# RP2040 register map
Vendor: Raspberry Pi; Series: RP; File version: 0.1
CPU: CM0PLUS r0p1, little endian, MPU, no FPU, VTOR, 2 interrupt priority bits, 32 interrupts
Registers are 32-bit, read-write, reset 0x0 unless marked. A register's access mark holds for its fields unless they carry their own. Offsets are from the block's base; [hi:lo] are bit positions; {n}, {i} and the like mark numbered series; 'fields as' and 'values as' point back to an identical list.

## IO_BANK0
Base 0x40014000
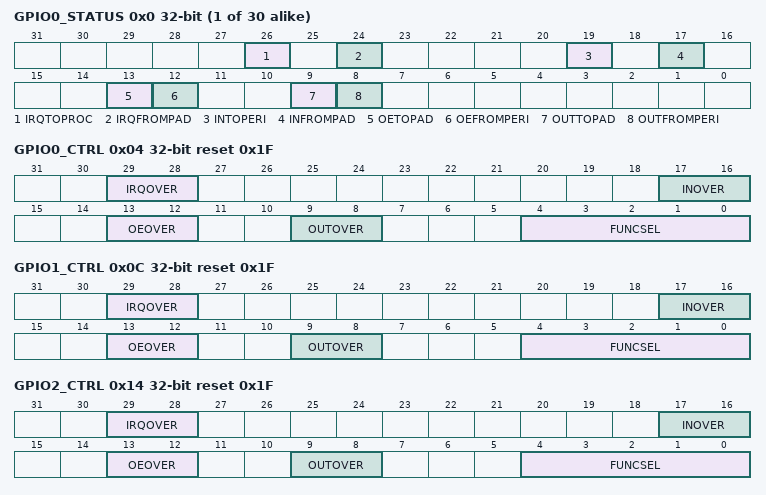
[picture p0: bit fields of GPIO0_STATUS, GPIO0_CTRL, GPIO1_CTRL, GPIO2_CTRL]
{0x0+8i} GPIO{i}_STATUS (i=0..29) — GPIO status
  [26] IRQTOPROC ro — interrupt to processors, after override is applied
  [24] IRQFROMPAD ro — interrupt from pad before override is applied
  [19] INTOPERI ro — input signal to peripheral, after override is applied
  [17] INFROMPAD ro — input signal from pad, before override is applied
  [13] OETOPAD ro — output enable to pad after register override is applied
  [12] OEFROMPERI ro — output enable from selected peripheral, before register override is applied
  [9] OUTTOPAD ro — output signal to pad after register override is applied
  [8] OUTFROMPERI ro — output signal from selected peripheral, before register override is applied
0x04 GPIO0_CTRL reset 0x1F — GPIO control including function select and overrides.
  [29:28] IRQOVER
    0=NORMAL (don't invert the interrupt); 1=INVERT (invert the interrupt); 2=LOW (drive interrupt low); 3=HIGH (drive interrupt high)
  [17:16] INOVER
    0=NORMAL (don't invert the peri input); 1=INVERT (invert the peri input); 2=LOW (drive peri input low); 3=HIGH (drive peri input high)
  [13:12] OEOVER
    0=NORMAL (drive output enable from peripheral signal selected by funcsel); 1=INVERT (drive output enable from inverse of peripheral signal selected by funcsel); 2=DISABLE (disable output); 3=ENABLE (enable output)
  [9:8] OUTOVER
    0=NORMAL (drive output from peripheral signal selected by funcsel); 1=INVERT (drive output from inverse of peripheral signal selected by funcsel); 2=LOW (drive output low); 3=HIGH (drive output high)
  [4:0] FUNCSEL — 0-31 -> selects pin function according to the gpio table 31 == NULL
    0=jtag_tck; 1=spi0_rx; 2=uart0_tx; 3=i2c0_sda; 4=pwm_a_0; 5=sio_0; 6=pio0_0; 7=pio1_0; 9=usb_muxing_overcurr_detect; 31=null
0x0C GPIO1_CTRL reset 0x1F — GPIO control including function select and overrides.
  [29:28] IRQOVER
    values as GPIO0_CTRL.IRQOVER
  [17:16] INOVER
    values as GPIO0_CTRL.INOVER
  [13:12] OEOVER
    values as GPIO0_CTRL.OEOVER
  [9:8] OUTOVER
    values as GPIO0_CTRL.OUTOVER
  [4:0] FUNCSEL — 0-31 -> selects pin function according to the gpio table 31 == NULL
    0=jtag_tms; 1=spi0_ss_n; 2=uart0_rx; 3=i2c0_scl; 4=pwm_b_0; 5=sio_1; 6=pio0_1; 7=pio1_1; 9=usb_muxing_vbus_detect; 31=null
0x14 GPIO2_CTRL reset 0x1F — GPIO control including function select and overrides.
  [29:28] IRQOVER
    values as GPIO0_CTRL.IRQOVER
  [17:16] INOVER
    values as GPIO0_CTRL.INOVER
  [13:12] OEOVER
    values as GPIO0_CTRL.OEOVER
  [9:8] OUTOVER
    values as GPIO0_CTRL.OUTOVER
  [4:0] FUNCSEL — 0-31 -> selects pin function according to the gpio table 31 == NULL
    0=jtag_tdi; 1=spi0_sclk; 2=uart0_cts; 3=i2c1_sda; 4=pwm_a_1; 5=sio_2; 6=pio0_2; 7=pio1_2; 9=usb_muxing_vbus_en; 31=null
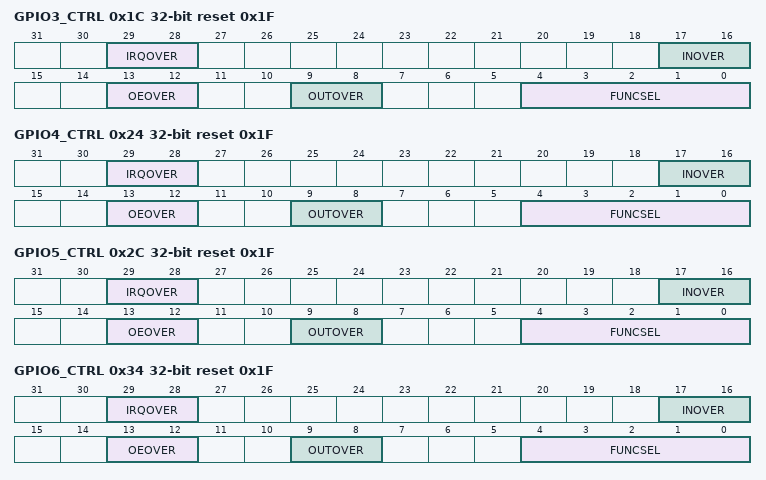
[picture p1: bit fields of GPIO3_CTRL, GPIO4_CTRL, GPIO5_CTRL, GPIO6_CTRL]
0x1C GPIO3_CTRL reset 0x1F — GPIO control including function select and overrides.
  [29:28] IRQOVER
    values as GPIO0_CTRL.IRQOVER
  [17:16] INOVER
    values as GPIO0_CTRL.INOVER
  [13:12] OEOVER
    values as GPIO0_CTRL.OEOVER
  [9:8] OUTOVER
    values as GPIO0_CTRL.OUTOVER
  [4:0] FUNCSEL — 0-31 -> selects pin function according to the gpio table 31 == NULL
    0=jtag_tdo; 1=spi0_tx; 2=uart0_rts; 3=i2c1_scl; 4=pwm_b_1; 5=sio_3; 6=pio0_3; 7=pio1_3; 9=usb_muxing_overcurr_detect; 31=null
0x24 GPIO4_CTRL reset 0x1F — GPIO control including function select and overrides.
  [29:28] IRQOVER
    values as GPIO0_CTRL.IRQOVER
  [17:16] INOVER
    values as GPIO0_CTRL.INOVER
  [13:12] OEOVER
    values as GPIO0_CTRL.OEOVER
  [9:8] OUTOVER
    values as GPIO0_CTRL.OUTOVER
  [4:0] FUNCSEL — 0-31 -> selects pin function according to the gpio table 31 == NULL
    1=spi0_rx; 2=uart1_tx; 3=i2c0_sda; 4=pwm_a_2; 5=sio_4; 6=pio0_4; 7=pio1_4; 9=usb_muxing_vbus_detect; 31=null
0x2C GPIO5_CTRL reset 0x1F — GPIO control including function select and overrides.
  [29:28] IRQOVER
    values as GPIO0_CTRL.IRQOVER
  [17:16] INOVER
    values as GPIO0_CTRL.INOVER
  [13:12] OEOVER
    values as GPIO0_CTRL.OEOVER
  [9:8] OUTOVER
    values as GPIO0_CTRL.OUTOVER
  [4:0] FUNCSEL — 0-31 -> selects pin function according to the gpio table 31 == NULL
    1=spi0_ss_n; 2=uart1_rx; 3=i2c0_scl; 4=pwm_b_2; 5=sio_5; 6=pio0_5; 7=pio1_5; 9=usb_muxing_vbus_en; 31=null
0x34 GPIO6_CTRL reset 0x1F — GPIO control including function select and overrides.
  [29:28] IRQOVER
    values as GPIO0_CTRL.IRQOVER
  [17:16] INOVER
    values as GPIO0_CTRL.INOVER
  [13:12] OEOVER
    values as GPIO0_CTRL.OEOVER
  [9:8] OUTOVER
    values as GPIO0_CTRL.OUTOVER
  [4:0] FUNCSEL — 0-31 -> selects pin function according to the gpio table 31 == NULL
    1=spi0_sclk; 2=uart1_cts; 3=i2c1_sda; 4=pwm_a_3; 5=sio_6; 6=pio0_6; 7=pio1_6; 8=usb_muxing_extphy_softcon; 9=usb_muxing_overcurr_detect; 31=null
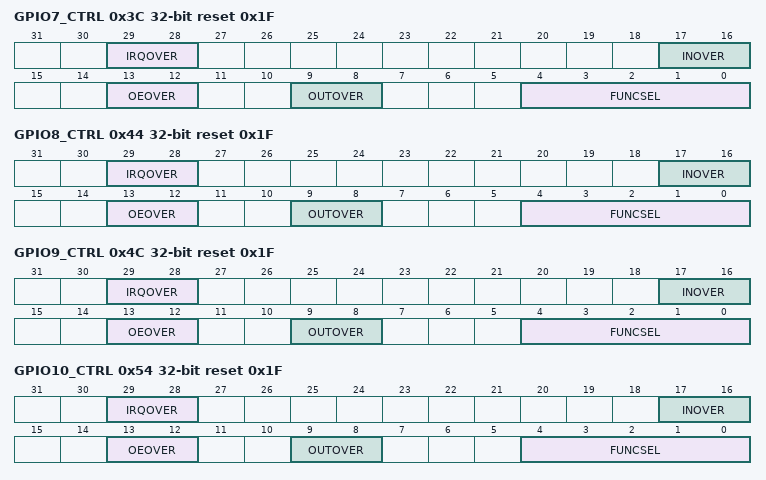
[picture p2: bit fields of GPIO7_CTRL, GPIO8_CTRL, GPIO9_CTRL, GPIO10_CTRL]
0x3C GPIO7_CTRL reset 0x1F — GPIO control including function select and overrides.
  [29:28] IRQOVER
    values as GPIO0_CTRL.IRQOVER
  [17:16] INOVER
    values as GPIO0_CTRL.INOVER
  [13:12] OEOVER
    values as GPIO0_CTRL.OEOVER
  [9:8] OUTOVER
    values as GPIO0_CTRL.OUTOVER
  [4:0] FUNCSEL — 0-31 -> selects pin function according to the gpio table 31 == NULL
    1=spi0_tx; 2=uart1_rts; 3=i2c1_scl; 4=pwm_b_3; 5=sio_7; 6=pio0_7; 7=pio1_7; 8=usb_muxing_extphy_oe_n; 9=usb_muxing_vbus_detect; 31=null
0x44 GPIO8_CTRL reset 0x1F — GPIO control including function select and overrides.
  [29:28] IRQOVER
    values as GPIO0_CTRL.IRQOVER
  [17:16] INOVER
    values as GPIO0_CTRL.INOVER
  [13:12] OEOVER
    values as GPIO0_CTRL.OEOVER
  [9:8] OUTOVER
    values as GPIO0_CTRL.OUTOVER
  [4:0] FUNCSEL — 0-31 -> selects pin function according to the gpio table 31 == NULL
    1=spi1_rx; 2=uart1_tx; 3=i2c0_sda; 4=pwm_a_4; 5=sio_8; 6=pio0_8; 7=pio1_8; 8=usb_muxing_extphy_rcv; 9=usb_muxing_vbus_en; 31=null
0x4C GPIO9_CTRL reset 0x1F — GPIO control including function select and overrides.
  [29:28] IRQOVER
    values as GPIO0_CTRL.IRQOVER
  [17:16] INOVER
    values as GPIO0_CTRL.INOVER
  [13:12] OEOVER
    values as GPIO0_CTRL.OEOVER
  [9:8] OUTOVER
    values as GPIO0_CTRL.OUTOVER
  [4:0] FUNCSEL — 0-31 -> selects pin function according to the gpio table 31 == NULL
    1=spi1_ss_n; 2=uart1_rx; 3=i2c0_scl; 4=pwm_b_4; 5=sio_9; 6=pio0_9; 7=pio1_9; 8=usb_muxing_extphy_vp; 9=usb_muxing_overcurr_detect; 31=null
0x54 GPIO10_CTRL reset 0x1F — GPIO control including function select and overrides.
  [29:28] IRQOVER
    values as GPIO0_CTRL.IRQOVER
  [17:16] INOVER
    values as GPIO0_CTRL.INOVER
  [13:12] OEOVER
    values as GPIO0_CTRL.OEOVER
  [9:8] OUTOVER
    values as GPIO0_CTRL.OUTOVER
  [4:0] FUNCSEL — 0-31 -> selects pin function according to the gpio table 31 == NULL
    1=spi1_sclk; 2=uart1_cts; 3=i2c1_sda; 4=pwm_a_5; 5=sio_10; 6=pio0_10; 7=pio1_10; 8=usb_muxing_extphy_vm; 9=usb_muxing_vbus_detect; 31=null
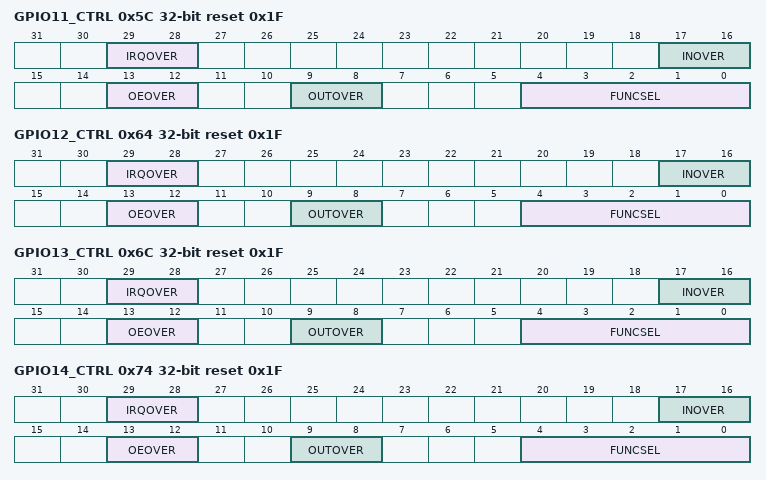
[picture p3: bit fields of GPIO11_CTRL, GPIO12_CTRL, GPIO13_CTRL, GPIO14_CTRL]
0x5C GPIO11_CTRL reset 0x1F — GPIO control including function select and overrides.
  [29:28] IRQOVER
    values as GPIO0_CTRL.IRQOVER
  [17:16] INOVER
    values as GPIO0_CTRL.INOVER
  [13:12] OEOVER
    values as GPIO0_CTRL.OEOVER
  [9:8] OUTOVER
    values as GPIO0_CTRL.OUTOVER
  [4:0] FUNCSEL — 0-31 -> selects pin function according to the gpio table 31 == NULL
    1=spi1_tx; 2=uart1_rts; 3=i2c1_scl; 4=pwm_b_5; 5=sio_11; 6=pio0_11; 7=pio1_11; 8=usb_muxing_extphy_suspnd; 9=usb_muxing_vbus_en; 31=null
0x64 GPIO12_CTRL reset 0x1F — GPIO control including function select and overrides.
  [29:28] IRQOVER
    values as GPIO0_CTRL.IRQOVER
  [17:16] INOVER
    values as GPIO0_CTRL.INOVER
  [13:12] OEOVER
    values as GPIO0_CTRL.OEOVER
  [9:8] OUTOVER
    values as GPIO0_CTRL.OUTOVER
  [4:0] FUNCSEL — 0-31 -> selects pin function according to the gpio table 31 == NULL
    1=spi1_rx; 2=uart0_tx; 3=i2c0_sda; 4=pwm_a_6; 5=sio_12; 6=pio0_12; 7=pio1_12; 8=usb_muxing_extphy_speed; 9=usb_muxing_overcurr_detect; 31=null
0x6C GPIO13_CTRL reset 0x1F — GPIO control including function select and overrides.
  [29:28] IRQOVER
    values as GPIO0_CTRL.IRQOVER
  [17:16] INOVER
    values as GPIO0_CTRL.INOVER
  [13:12] OEOVER
    values as GPIO0_CTRL.OEOVER
  [9:8] OUTOVER
    values as GPIO0_CTRL.OUTOVER
  [4:0] FUNCSEL — 0-31 -> selects pin function according to the gpio table 31 == NULL
    1=spi1_ss_n; 2=uart0_rx; 3=i2c0_scl; 4=pwm_b_6; 5=sio_13; 6=pio0_13; 7=pio1_13; 8=usb_muxing_extphy_vpo; 9=usb_muxing_vbus_detect; 31=null
0x74 GPIO14_CTRL reset 0x1F — GPIO control including function select and overrides.
  [29:28] IRQOVER
    values as GPIO0_CTRL.IRQOVER
  [17:16] INOVER
    values as GPIO0_CTRL.INOVER
  [13:12] OEOVER
    values as GPIO0_CTRL.OEOVER
  [9:8] OUTOVER
    values as GPIO0_CTRL.OUTOVER
  [4:0] FUNCSEL — 0-31 -> selects pin function according to the gpio table 31 == NULL
    1=spi1_sclk; 2=uart0_cts; 3=i2c1_sda; 4=pwm_a_7; 5=sio_14; 6=pio0_14; 7=pio1_14; 8=usb_muxing_extphy_vmo; 9=usb_muxing_vbus_en; 31=null
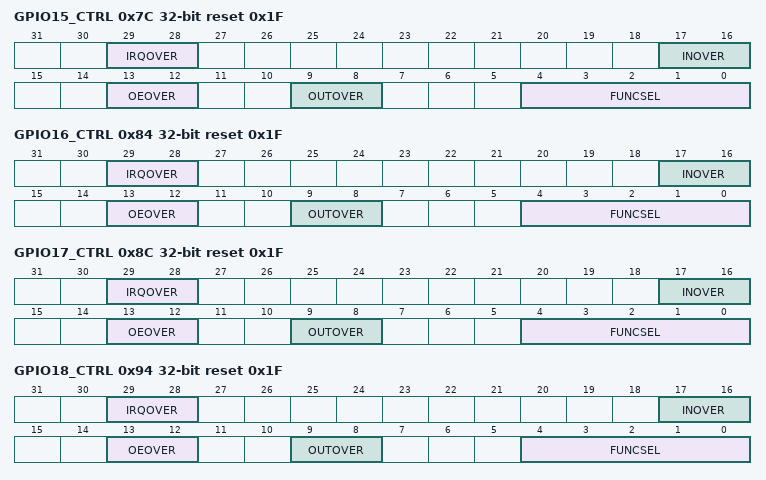
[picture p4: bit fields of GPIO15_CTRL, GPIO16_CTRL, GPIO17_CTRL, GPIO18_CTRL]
0x7C GPIO15_CTRL reset 0x1F — GPIO control including function select and overrides.
  [29:28] IRQOVER
    values as GPIO0_CTRL.IRQOVER
  [17:16] INOVER
    values as GPIO0_CTRL.INOVER
  [13:12] OEOVER
    values as GPIO0_CTRL.OEOVER
  [9:8] OUTOVER
    values as GPIO0_CTRL.OUTOVER
  [4:0] FUNCSEL — 0-31 -> selects pin function according to the gpio table 31 == NULL
    1=spi1_tx; 2=uart0_rts; 3=i2c1_scl; 4=pwm_b_7; 5=sio_15; 6=pio0_15; 7=pio1_15; 8=usb_muxing_digital_dp; 9=usb_muxing_overcurr_detect; 31=null
0x84 GPIO16_CTRL reset 0x1F — GPIO control including function select and overrides.
  [29:28] IRQOVER
    values as GPIO0_CTRL.IRQOVER
  [17:16] INOVER
    values as GPIO0_CTRL.INOVER
  [13:12] OEOVER
    values as GPIO0_CTRL.OEOVER
  [9:8] OUTOVER
    values as GPIO0_CTRL.OUTOVER
  [4:0] FUNCSEL — 0-31 -> selects pin function according to the gpio table 31 == NULL
    1=spi0_rx; 2=uart0_tx; 3=i2c0_sda; 4=pwm_a_0; 5=sio_16; 6=pio0_16; 7=pio1_16; 8=usb_muxing_digital_dm; 9=usb_muxing_vbus_detect; 31=null
0x8C GPIO17_CTRL reset 0x1F — GPIO control including function select and overrides.
  [29:28] IRQOVER
    values as GPIO0_CTRL.IRQOVER
  [17:16] INOVER
    values as GPIO0_CTRL.INOVER
  [13:12] OEOVER
    values as GPIO0_CTRL.OEOVER
  [9:8] OUTOVER
    values as GPIO0_CTRL.OUTOVER
  [4:0] FUNCSEL — 0-31 -> selects pin function according to the gpio table 31 == NULL
    1=spi0_ss_n; 2=uart0_rx; 3=i2c0_scl; 4=pwm_b_0; 5=sio_17; 6=pio0_17; 7=pio1_17; 9=usb_muxing_vbus_en; 31=null
0x94 GPIO18_CTRL reset 0x1F — GPIO control including function select and overrides.
  [29:28] IRQOVER
    values as GPIO0_CTRL.IRQOVER
  [17:16] INOVER
    values as GPIO0_CTRL.INOVER
  [13:12] OEOVER
    values as GPIO0_CTRL.OEOVER
  [9:8] OUTOVER
    values as GPIO0_CTRL.OUTOVER
  [4:0] FUNCSEL — 0-31 -> selects pin function according to the gpio table 31 == NULL
    1=spi0_sclk; 2=uart0_cts; 3=i2c1_sda; 4=pwm_a_1; 5=sio_18; 6=pio0_18; 7=pio1_18; 9=usb_muxing_overcurr_detect; 31=null
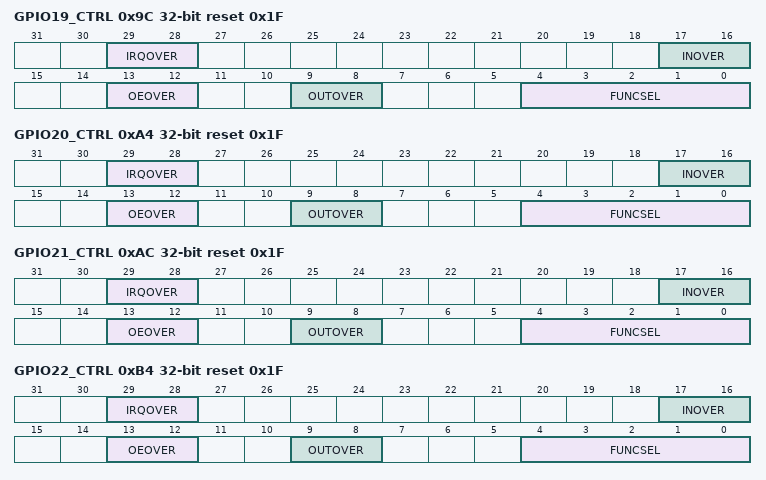
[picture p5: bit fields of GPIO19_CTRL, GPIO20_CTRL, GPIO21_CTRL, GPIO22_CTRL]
0x9C GPIO19_CTRL reset 0x1F — GPIO control including function select and overrides.
  [29:28] IRQOVER
    values as GPIO0_CTRL.IRQOVER
  [17:16] INOVER
    values as GPIO0_CTRL.INOVER
  [13:12] OEOVER
    values as GPIO0_CTRL.OEOVER
  [9:8] OUTOVER
    values as GPIO0_CTRL.OUTOVER
  [4:0] FUNCSEL — 0-31 -> selects pin function according to the gpio table 31 == NULL
    1=spi0_tx; 2=uart0_rts; 3=i2c1_scl; 4=pwm_b_1; 5=sio_19; 6=pio0_19; 7=pio1_19; 9=usb_muxing_vbus_detect; 31=null
0xA4 GPIO20_CTRL reset 0x1F — GPIO control including function select and overrides.
  [29:28] IRQOVER
    values as GPIO0_CTRL.IRQOVER
  [17:16] INOVER
    values as GPIO0_CTRL.INOVER
  [13:12] OEOVER
    values as GPIO0_CTRL.OEOVER
  [9:8] OUTOVER
    values as GPIO0_CTRL.OUTOVER
  [4:0] FUNCSEL — 0-31 -> selects pin function according to the gpio table 31 == NULL
    1=spi0_rx; 2=uart1_tx; 3=i2c0_sda; 4=pwm_a_2; 5=sio_20; 6=pio0_20; 7=pio1_20; 8=clocks_gpin_0; 9=usb_muxing_vbus_en; 31=null
0xAC GPIO21_CTRL reset 0x1F — GPIO control including function select and overrides.
  [29:28] IRQOVER
    values as GPIO0_CTRL.IRQOVER
  [17:16] INOVER
    values as GPIO0_CTRL.INOVER
  [13:12] OEOVER
    values as GPIO0_CTRL.OEOVER
  [9:8] OUTOVER
    values as GPIO0_CTRL.OUTOVER
  [4:0] FUNCSEL — 0-31 -> selects pin function according to the gpio table 31 == NULL
    1=spi0_ss_n; 2=uart1_rx; 3=i2c0_scl; 4=pwm_b_2; 5=sio_21; 6=pio0_21; 7=pio1_21; 8=clocks_gpout_0; 9=usb_muxing_overcurr_detect; 31=null
0xB4 GPIO22_CTRL reset 0x1F — GPIO control including function select and overrides.
  [29:28] IRQOVER
    values as GPIO0_CTRL.IRQOVER
  [17:16] INOVER
    values as GPIO0_CTRL.INOVER
  [13:12] OEOVER
    values as GPIO0_CTRL.OEOVER
  [9:8] OUTOVER
    values as GPIO0_CTRL.OUTOVER
  [4:0] FUNCSEL — 0-31 -> selects pin function according to the gpio table 31 == NULL
    1=spi0_sclk; 2=uart1_cts; 3=i2c1_sda; 4=pwm_a_3; 5=sio_22; 6=pio0_22; 7=pio1_22; 8=clocks_gpin_1; 9=usb_muxing_vbus_detect; 31=null
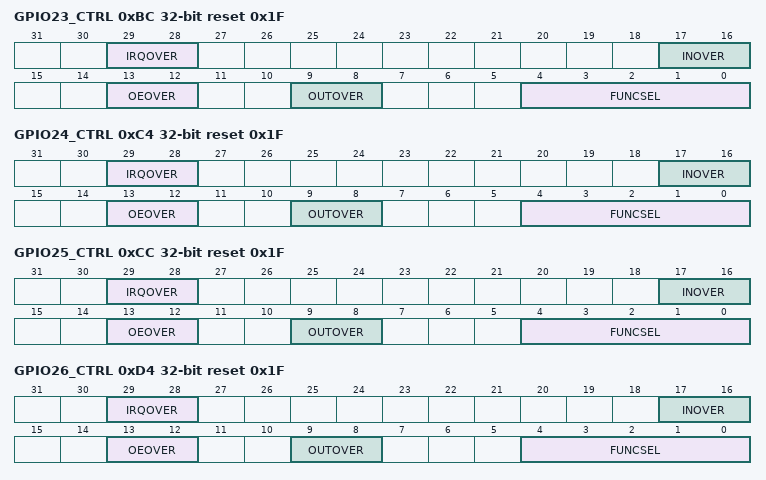
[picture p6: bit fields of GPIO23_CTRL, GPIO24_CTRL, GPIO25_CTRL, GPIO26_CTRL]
0xBC GPIO23_CTRL reset 0x1F — GPIO control including function select and overrides.
  [29:28] IRQOVER
    values as GPIO0_CTRL.IRQOVER
  [17:16] INOVER
    values as GPIO0_CTRL.INOVER
  [13:12] OEOVER
    values as GPIO0_CTRL.OEOVER
  [9:8] OUTOVER
    values as GPIO0_CTRL.OUTOVER
  [4:0] FUNCSEL — 0-31 -> selects pin function according to the gpio table 31 == NULL
    1=spi0_tx; 2=uart1_rts; 3=i2c1_scl; 4=pwm_b_3; 5=sio_23; 6=pio0_23; 7=pio1_23; 8=clocks_gpout_1; 9=usb_muxing_vbus_en; 31=null
0xC4 GPIO24_CTRL reset 0x1F — GPIO control including function select and overrides.
  [29:28] IRQOVER
    values as GPIO0_CTRL.IRQOVER
  [17:16] INOVER
    values as GPIO0_CTRL.INOVER
  [13:12] OEOVER
    values as GPIO0_CTRL.OEOVER
  [9:8] OUTOVER
    values as GPIO0_CTRL.OUTOVER
  [4:0] FUNCSEL — 0-31 -> selects pin function according to the gpio table 31 == NULL
    1=spi1_rx; 2=uart1_tx; 3=i2c0_sda; 4=pwm_a_4; 5=sio_24; 6=pio0_24; 7=pio1_24; 8=clocks_gpout_2; 9=usb_muxing_overcurr_detect; 31=null
0xCC GPIO25_CTRL reset 0x1F — GPIO control including function select and overrides.
  [29:28] IRQOVER
    values as GPIO0_CTRL.IRQOVER
  [17:16] INOVER
    values as GPIO0_CTRL.INOVER
  [13:12] OEOVER
    values as GPIO0_CTRL.OEOVER
  [9:8] OUTOVER
    values as GPIO0_CTRL.OUTOVER
  [4:0] FUNCSEL — 0-31 -> selects pin function according to the gpio table 31 == NULL
    1=spi1_ss_n; 2=uart1_rx; 3=i2c0_scl; 4=pwm_b_4; 5=sio_25; 6=pio0_25; 7=pio1_25; 8=clocks_gpout_3; 9=usb_muxing_vbus_detect; 31=null
0xD4 GPIO26_CTRL reset 0x1F — GPIO control including function select and overrides.
  [29:28] IRQOVER
    values as GPIO0_CTRL.IRQOVER
  [17:16] INOVER
    values as GPIO0_CTRL.INOVER
  [13:12] OEOVER
    values as GPIO0_CTRL.OEOVER
  [9:8] OUTOVER
    values as GPIO0_CTRL.OUTOVER
  [4:0] FUNCSEL — 0-31 -> selects pin function according to the gpio table 31 == NULL
    1=spi1_sclk; 2=uart1_cts; 3=i2c1_sda; 4=pwm_a_5; 5=sio_26; 6=pio0_26; 7=pio1_26; 9=usb_muxing_vbus_en; 31=null
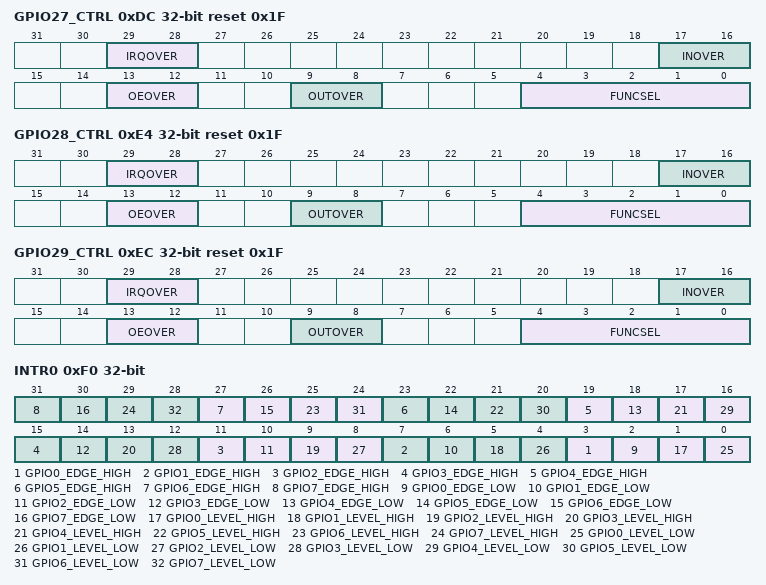
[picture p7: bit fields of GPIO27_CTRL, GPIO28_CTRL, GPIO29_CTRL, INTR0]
0xDC GPIO27_CTRL reset 0x1F — GPIO control including function select and overrides.
  [29:28] IRQOVER
    values as GPIO0_CTRL.IRQOVER
  [17:16] INOVER
    values as GPIO0_CTRL.INOVER
  [13:12] OEOVER
    values as GPIO0_CTRL.OEOVER
  [9:8] OUTOVER
    values as GPIO0_CTRL.OUTOVER
  [4:0] FUNCSEL — 0-31 -> selects pin function according to the gpio table 31 == NULL
    1=spi1_tx; 2=uart1_rts; 3=i2c1_scl; 4=pwm_b_5; 5=sio_27; 6=pio0_27; 7=pio1_27; 9=usb_muxing_overcurr_detect; 31=null
0xE4 GPIO28_CTRL reset 0x1F — GPIO control including function select and overrides.
  [29:28] IRQOVER
    values as GPIO0_CTRL.IRQOVER
  [17:16] INOVER
    values as GPIO0_CTRL.INOVER
  [13:12] OEOVER
    values as GPIO0_CTRL.OEOVER
  [9:8] OUTOVER
    values as GPIO0_CTRL.OUTOVER
  [4:0] FUNCSEL — 0-31 -> selects pin function according to the gpio table 31 == NULL
    1=spi1_rx; 2=uart0_tx; 3=i2c0_sda; 4=pwm_a_6; 5=sio_28; 6=pio0_28; 7=pio1_28; 9=usb_muxing_vbus_detect; 31=null
0xEC GPIO29_CTRL reset 0x1F — GPIO control including function select and overrides.
  [29:28] IRQOVER
    values as GPIO0_CTRL.IRQOVER
  [17:16] INOVER
    values as GPIO0_CTRL.INOVER
  [13:12] OEOVER
    values as GPIO0_CTRL.OEOVER
  [9:8] OUTOVER
    values as GPIO0_CTRL.OUTOVER
  [4:0] FUNCSEL — 0-31 -> selects pin function according to the gpio table 31 == NULL
    1=spi1_ss_n; 2=uart0_rx; 3=i2c0_scl; 4=pwm_b_6; 5=sio_29; 6=pio0_29; 7=pio1_29; 9=usb_muxing_vbus_en; 31=null
0xF0 INTR0 — Raw Interrupts
  [4n+3] GPIO{n}_EDGE_HIGH write-1-clears (n=0..7), [4n+2] GPIO{n}_EDGE_LOW write-1-clears (n=0..7), [4n+1] GPIO{n}_LEVEL_HIGH ro (n=0..7), [4n] GPIO{n}_LEVEL_LOW ro (n=0..7)
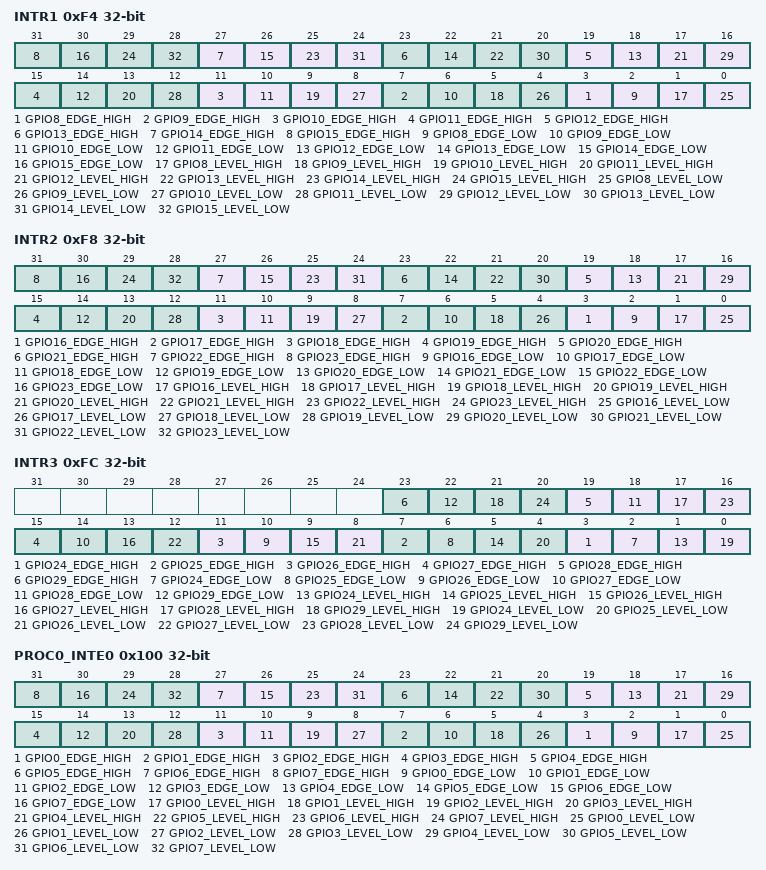
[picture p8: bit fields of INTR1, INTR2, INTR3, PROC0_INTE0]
0xF4 INTR1 — Raw Interrupts
  [4n-29] GPIO{n}_EDGE_HIGH write-1-clears (n=8..15), [4n-30] GPIO{n}_EDGE_LOW write-1-clears (n=8..15), [4n-31] GPIO{n}_LEVEL_HIGH ro (n=8..15), [4n-32] GPIO{n}_LEVEL_LOW ro (n=8..15)
0xF8 INTR2 — Raw Interrupts
  [4n-61] GPIO{n}_EDGE_HIGH write-1-clears (n=16..23), [4n-62] GPIO{n}_EDGE_LOW write-1-clears (n=16..23), [4n-63] GPIO{n}_LEVEL_HIGH ro (n=16..23), [4n-64] GPIO{n}_LEVEL_LOW ro (n=16..23)
0xFC INTR3 — Raw Interrupts
  [4n-93] GPIO{n}_EDGE_HIGH write-1-clears (n=24..29), [4n-94] GPIO{n}_EDGE_LOW write-1-clears (n=24..29), [4n-95] GPIO{n}_LEVEL_HIGH ro (n=24..29), [4n-96] GPIO{n}_LEVEL_LOW ro (n=24..29)
0x100 PROC0_INTE0 — Interrupt Enable for proc0
  [4n+3] GPIO{n}_EDGE_HIGH (n=0..7), [4n+2] GPIO{n}_EDGE_LOW (n=0..7), [4n+1] GPIO{n}_LEVEL_HIGH (n=0..7), [4n] GPIO{n}_LEVEL_LOW (n=0..7)
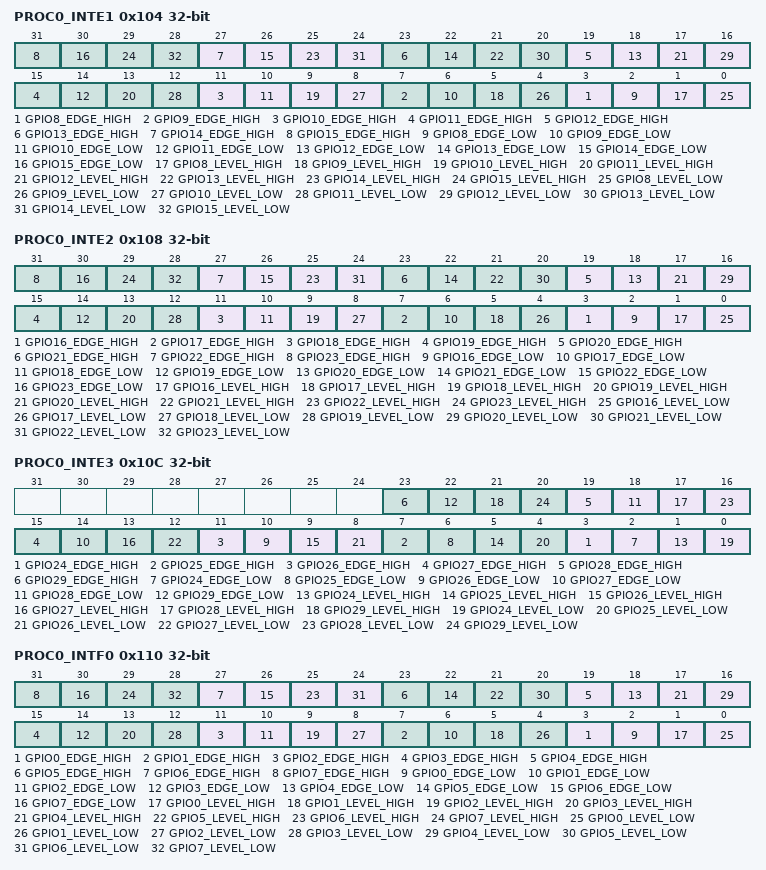
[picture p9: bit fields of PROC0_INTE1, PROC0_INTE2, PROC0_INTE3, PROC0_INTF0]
0x104 PROC0_INTE1 — Interrupt Enable for proc0
  [4n-29] GPIO{n}_EDGE_HIGH (n=8..15), [4n-30] GPIO{n}_EDGE_LOW (n=8..15), [4n-31] GPIO{n}_LEVEL_HIGH (n=8..15), [4n-32] GPIO{n}_LEVEL_LOW (n=8..15)
0x108 PROC0_INTE2 — Interrupt Enable for proc0
  [4n-61] GPIO{n}_EDGE_HIGH (n=16..23), [4n-62] GPIO{n}_EDGE_LOW (n=16..23), [4n-63] GPIO{n}_LEVEL_HIGH (n=16..23), [4n-64] GPIO{n}_LEVEL_LOW (n=16..23)
0x10C PROC0_INTE3 — Interrupt Enable for proc0
  [4n-93] GPIO{n}_EDGE_HIGH (n=24..29), [4n-94] GPIO{n}_EDGE_LOW (n=24..29), [4n-95] GPIO{n}_LEVEL_HIGH (n=24..29), [4n-96] GPIO{n}_LEVEL_LOW (n=24..29)
0x110 PROC0_INTF0 — Interrupt Force for proc0
  fields as PROC0_INTE0
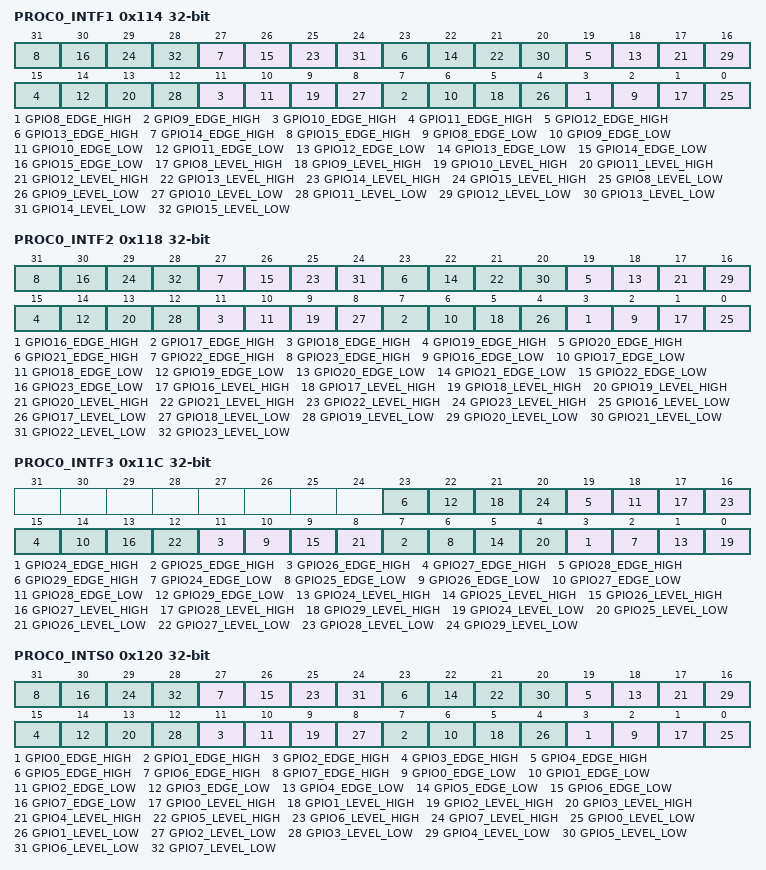
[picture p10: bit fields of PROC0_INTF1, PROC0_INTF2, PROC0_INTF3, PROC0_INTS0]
0x114 PROC0_INTF1 — Interrupt Force for proc0
  fields as PROC0_INTE1
0x118 PROC0_INTF2 — Interrupt Force for proc0
  fields as PROC0_INTE2
0x11C PROC0_INTF3 — Interrupt Force for proc0
  fields as PROC0_INTE3
0x120 PROC0_INTS0 — Interrupt status after masking & forcing for proc0
  [4n+3] GPIO{n}_EDGE_HIGH ro (n=0..7), [4n+2] GPIO{n}_EDGE_LOW ro (n=0..7), [4n+1] GPIO{n}_LEVEL_HIGH ro (n=0..7), [4n] GPIO{n}_LEVEL_LOW ro (n=0..7)
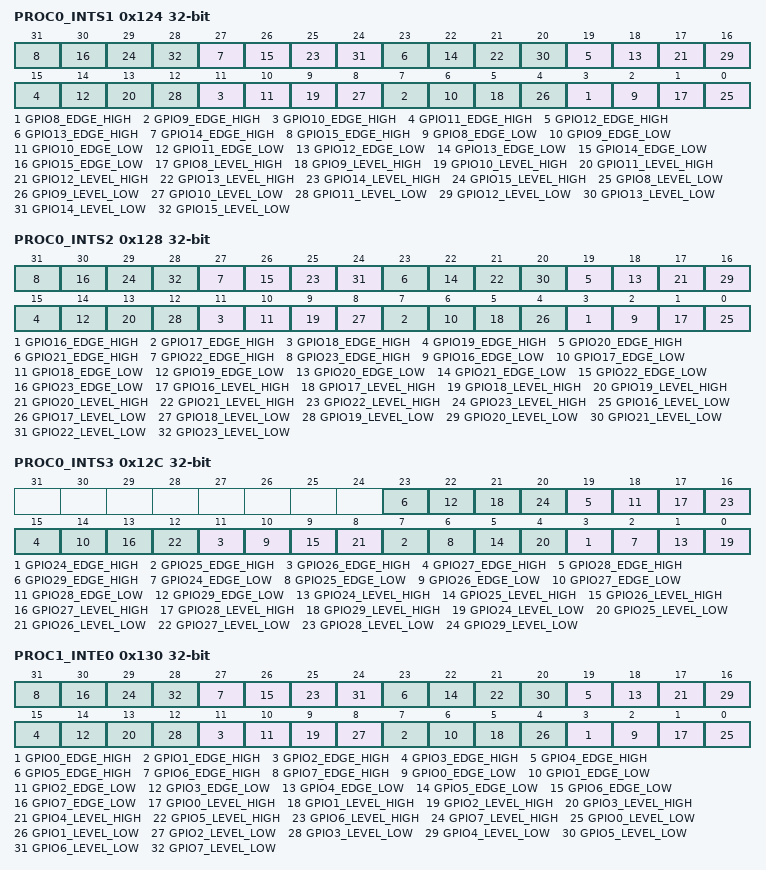
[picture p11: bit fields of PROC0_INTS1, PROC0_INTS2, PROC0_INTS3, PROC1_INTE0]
0x124 PROC0_INTS1 — Interrupt status after masking & forcing for proc0
  [4n-29] GPIO{n}_EDGE_HIGH ro (n=8..15), [4n-30] GPIO{n}_EDGE_LOW ro (n=8..15), [4n-31] GPIO{n}_LEVEL_HIGH ro (n=8..15), [4n-32] GPIO{n}_LEVEL_LOW ro (n=8..15)
0x128 PROC0_INTS2 — Interrupt status after masking & forcing for proc0
  [4n-61] GPIO{n}_EDGE_HIGH ro (n=16..23), [4n-62] GPIO{n}_EDGE_LOW ro (n=16..23), [4n-63] GPIO{n}_LEVEL_HIGH ro (n=16..23), [4n-64] GPIO{n}_LEVEL_LOW ro (n=16..23)
0x12C PROC0_INTS3 — Interrupt status after masking & forcing for proc0
  [4n-93] GPIO{n}_EDGE_HIGH ro (n=24..29), [4n-94] GPIO{n}_EDGE_LOW ro (n=24..29), [4n-95] GPIO{n}_LEVEL_HIGH ro (n=24..29), [4n-96] GPIO{n}_LEVEL_LOW ro (n=24..29)
0x130 PROC1_INTE0 — Interrupt Enable for proc1
  fields as PROC0_INTE0
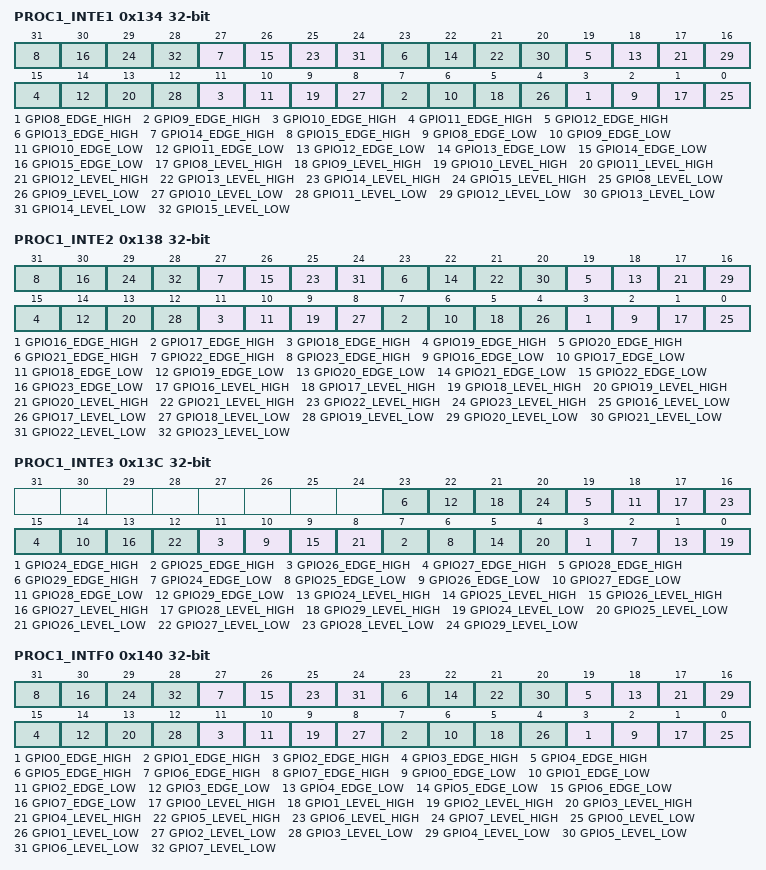
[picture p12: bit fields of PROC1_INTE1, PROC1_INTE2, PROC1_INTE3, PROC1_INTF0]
0x134 PROC1_INTE1 — Interrupt Enable for proc1
  fields as PROC0_INTE1
0x138 PROC1_INTE2 — Interrupt Enable for proc1
  fields as PROC0_INTE2
0x13C PROC1_INTE3 — Interrupt Enable for proc1
  fields as PROC0_INTE3
0x140 PROC1_INTF0 — Interrupt Force for proc1
  fields as PROC0_INTE0
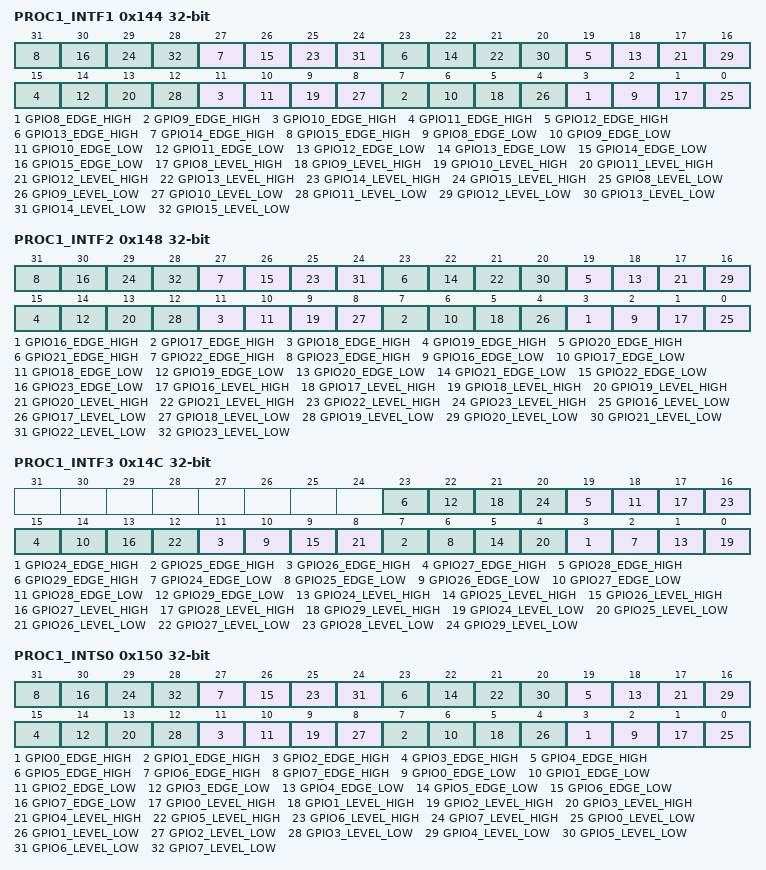
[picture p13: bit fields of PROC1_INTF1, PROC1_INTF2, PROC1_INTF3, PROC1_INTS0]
0x144 PROC1_INTF1 — Interrupt Force for proc1
  fields as PROC0_INTE1
0x148 PROC1_INTF2 — Interrupt Force for proc1
  fields as PROC0_INTE2
0x14C PROC1_INTF3 — Interrupt Force for proc1
  fields as PROC0_INTE3
0x150 PROC1_INTS0 — Interrupt status after masking & forcing for proc1
  fields as PROC0_INTS0
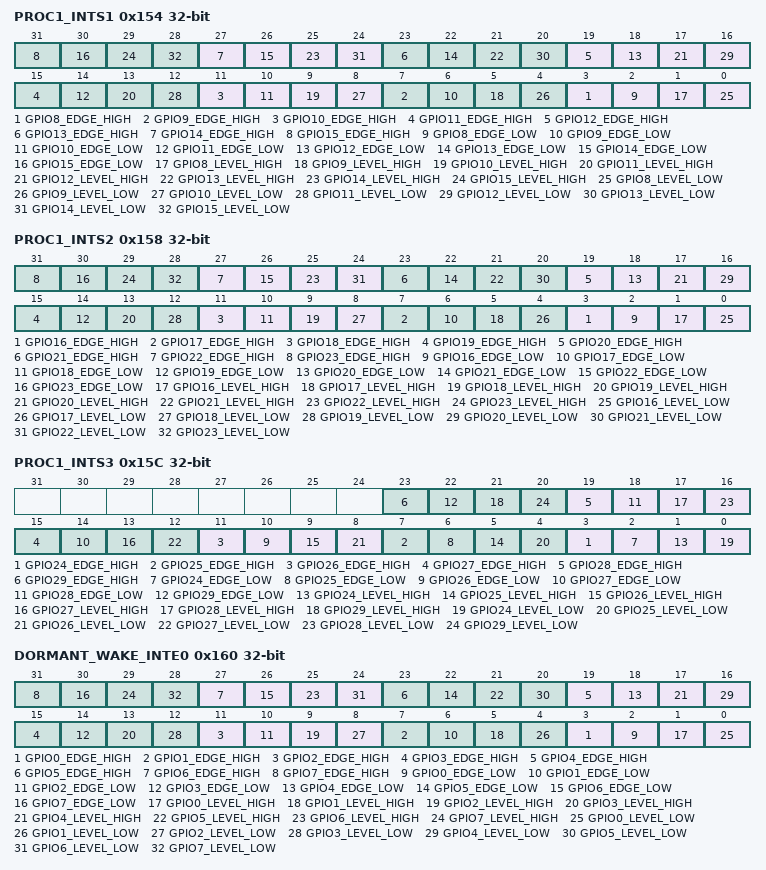
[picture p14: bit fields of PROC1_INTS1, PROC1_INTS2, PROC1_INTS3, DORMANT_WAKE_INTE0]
0x154 PROC1_INTS1 — Interrupt status after masking & forcing for proc1
  fields as PROC0_INTS1
0x158 PROC1_INTS2 — Interrupt status after masking & forcing for proc1
  fields as PROC0_INTS2
0x15C PROC1_INTS3 — Interrupt status after masking & forcing for proc1
  fields as PROC0_INTS3
0x160 DORMANT_WAKE_INTE0 — Interrupt Enable for dormant_wake
  fields as PROC0_INTE0
0x164 DORMANT_WAKE_INTE1 — Interrupt Enable for dormant_wake
  fields as PROC0_INTE1
0x168 DORMANT_WAKE_INTE2 — Interrupt Enable for dormant_wake
  fields as PROC0_INTE2
0x16C DORMANT_WAKE_INTE3 — Interrupt Enable for dormant_wake
  fields as PROC0_INTE3
0x170 DORMANT_WAKE_INTF0 — Interrupt Force for dormant_wake
  fields as PROC0_INTE0
0x174 DORMANT_WAKE_INTF1 — Interrupt Force for dormant_wake
  fields as PROC0_INTE1
0x178 DORMANT_WAKE_INTF2 — Interrupt Force for dormant_wake
  fields as PROC0_INTE2
0x17C DORMANT_WAKE_INTF3 — Interrupt Force for dormant_wake
  fields as PROC0_INTE3
0x180 DORMANT_WAKE_INTS0 — Interrupt status after masking & forcing for dormant_wake
  fields as PROC0_INTS0
0x184 DORMANT_WAKE_INTS1 — Interrupt status after masking & forcing for dormant_wake
  fields as PROC0_INTS1
0x188 DORMANT_WAKE_INTS2 — Interrupt status after masking & forcing for dormant_wake
  fields as PROC0_INTS2
0x18C DORMANT_WAKE_INTS3 — Interrupt status after masking & forcing for dormant_wake
  fields as PROC0_INTS3
